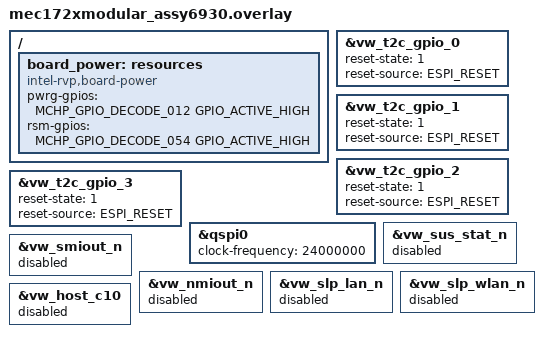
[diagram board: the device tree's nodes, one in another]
/*
 * Copyright (c) 2020 Intel Corporation
 *
 * SPDX-License-Identifier: Apache-2.0
 */

/ {
	board_power: resources {
		compatible = "intel-rvp,board-power";
		pwrg-gpios = <MCHP_GPIO_DECODE_012 GPIO_ACTIVE_HIGH>;
		rsm-gpios = <MCHP_GPIO_DECODE_054 GPIO_ACTIVE_HIGH>;
	};
};

/* Enable Target to Controller Virtual Wires GPIO 0 - 3 */
&vw_t2c_gpio_0 {
	reset-state = "1";
	reset-source = "ESPI_RESET";
	status = "okay";
};

&vw_t2c_gpio_1 {
	reset-state = "1";
	reset-source = "ESPI_RESET";
	status = "okay";
};

&vw_t2c_gpio_2 {
	reset-state = "1";
	reset-source = "ESPI_RESET";
	status = "okay";
};

&vw_t2c_gpio_3 {
	reset-state = "1";
	reset-source = "ESPI_RESET";
	status = "okay";
};

&qspi0 {
	clock-frequency = <24000000>;
	status = "okay";
};

/* Disable unwanted VWs notifications
 * Refer to include/zephyr/drivers/espi.h
 */
&vw_sus_stat_n {
	status = "disabled";
};

&vw_smiout_n {
	status = "disabled";
};

&vw_nmiout_n {
	status = "disabled";
};

&vw_slp_lan_n {
	status = "disabled";
};

&vw_slp_wlan_n {
	status = "disabled";
};

&vw_host_c10 {
	status = "disabled";
};
